# STM32F303VCY7 register map
File version: 1.0
STM32F303CBT6,STM32F303CBT7,STM32F303CCT6,STM32F303CCT7,STM32F303RBT6,STM32F303RBT7,STM32F303RCT6,STM32F303RCT7,STM32F303VBT6,STM32F303VBT7,STM32F303VCT6,STM32F303VCT7,STM32F303VCY6,STM32F303VCY7
Registers are 32-bit, access not given, reset 0x0 unless marked. A register's access mark holds for its fields unless they carry their own. Offsets are from the block's base; lines under a group give offsets from that group; [hi:lo] are bit positions; {n}, {i} and the like mark numbered series; 'fields as' and 'values as' point back to an identical list; <NAME> marks a mode.

## Memory map
0x1FFFF800 OB
0x40000000 TIM2
0x40000400 TIM3
0x40000800 TIM4
0x40001000 TIM6
0x40001400 TIM7
0x40002800 RTC
0x40002C00 WWDG
0x40003000 IWDG
0x40003400 I2S2ext
0x40003800 SPI2
0x40003C00 SPI3
0x40004000 I2S3ext
0x40004400 USART2
0x40004800 USART3
0x40004C00 UART4
0x40005000 UART5
0x40005400 I2C1
0x40005800 I2C2
0x40006400 CAN
0x40007000 PWR
0x40007400 DAC
0x40007400 DAC1
0x40010000 SYSCFG
0x4001001C COMP1
0x4001001C COMP
0x40010020 COMP2
0x40010020 COMP12_COMMON
0x40010024 COMP3
0x40010028 COMP4
0x40010028 COMP34_COMMON
0x4001002C COMP5
0x40010030 COMP6
0x40010030 COMP56_COMMON
0x40010034 COMP7
0x40010038 OPAMP1
0x40010038 OPAMP
0x4001003C OPAMP2
0x40010040 OPAMP3
0x40010044 OPAMP4
0x40010400 EXTI
0x40012C00 TIM1
0x40013000 SPI1
0x40013400 TIM8
0x40013800 USART1
0x40014000 TIM15
0x40014400 TIM16
0x40014800 TIM17
0x40020000 DMA1
0x40020400 DMA2
0x40021000 RCC
0x40022000 FLASH
0x40023000 CRC
0x40024000 TSC
0x48000000 GPIOA
0x48000400 GPIOB
0x48000800 GPIOC
0x48000C00 GPIOD
0x48001000 GPIOE
0x48001400 GPIOF
0x50000000 ADC1
0x50000100 ADC2
0x50000300 ADC12_COMMON
0x50000400 ADC3
0x50000500 ADC4
0x50000700 ADC34_COMMON
0xE0042000 DBGMCU

## OB
Base 0x1FFFF800
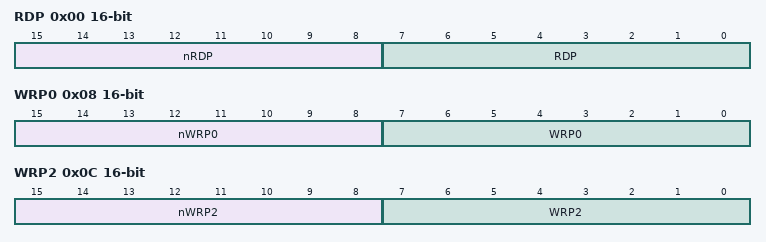
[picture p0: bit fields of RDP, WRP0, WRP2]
0x00 RDP 16-bit
  [15:8] nRDP, [7:0] RDP
0x02 USER 16-bit
  [31:24] nUSER, [23:16] USER
0x04 Data0 16-bit
0x06 Data1 16-bit
0x08 WRP0 16-bit
  [15:8] nWRP0, [7:0] WRP0
0x0A WRP1 16-bit
  [31:24] nWRP1, [23:16] WRP1
0x0C WRP2 16-bit
  [15:8] nWRP2, [7:0] WRP2
0x0E WRP3 16-bit
  [31:24] nWRP3, [23:16] WRP3

## TIM2
Base 0x40000000
Same registers: TIM3 0x40000400, TIM4 0x40000800, TIM6 0x40001000, TIM7 0x40001400, TIM1 0x40012C00, TIM8 0x40013400, TIM15 0x40014000, TIM16 0x40014400, TIM17 0x40014800
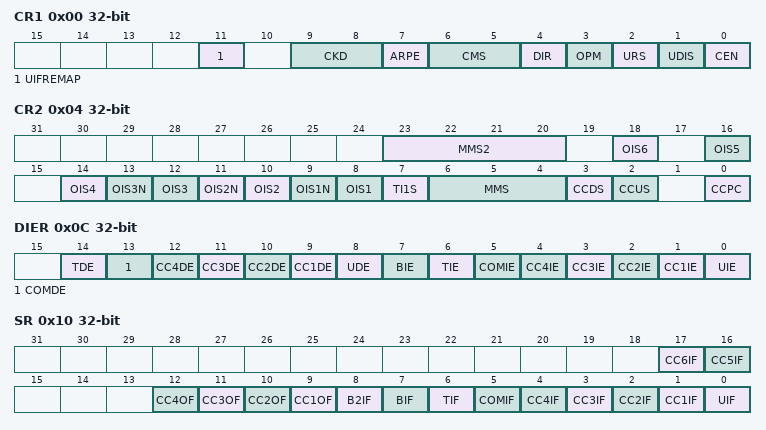
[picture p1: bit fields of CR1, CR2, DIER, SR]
0x00 CR1
  [11] UIFREMAP, [9:8] CKD, [7] ARPE, [6:5] CMS, [4] DIR, [3] OPM, [2] URS, [1] UDIS, [0] CEN
0x04 CR2
  [23:20] MMS2, [2n+6] OIS{n} (n=1..6), [13] OIS3N, [11] OIS2N, [9] OIS1N, [7] TI1S, [6:4] MMS, [3] CCDS, [2] CCUS, [0] CCPC
0x08 SMCR
  [15] ETP, [14] ECE, [13:12] ETPS, [11:8] ETF, [7] MSM, [6:4] TS, [3] OCCS, [16:0] SMS
0x0C DIER
  [14] TDE, [13] COMDE, [n+8] CC{n}DE (n=1..4), [8] UDE, [7] BIE, [6] TIE, [5] COMIE, [n] CC{n}IE (n=1..4), [0] UIE
0x10 SR
  [17] CC6IF, [16] CC5IF, [n+8] CC{n}OF (n=1..4), [8] B2IF, [7] BIF, [6] TIF, [5] COMIF, [n] CC{n}IF (n=1..4), [0] UIF
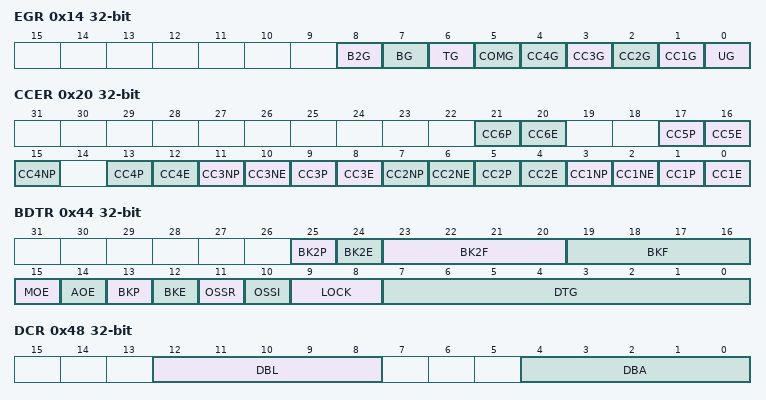
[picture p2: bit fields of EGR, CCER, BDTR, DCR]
0x14 EGR
  [8] B2G, [7] BG, [6] TG, [5] COMG, [n] CC{n}G (n=1..4), [0] UG
0x18 CCMR1
  [15] OC2CE, [24:12] OC2M, [11] OC2PE, [10] OC2FE, [9:8] CC2S, [7] OC1CE, [16:4] OC1M, [3] OC1PE, [2] OC1FE, [1:0] CC1S
0x1C CCMR2
  [15] OC4CE, [24:12] OC4M, [11] OC4PE, [10] OC4FE, [9:8] CC4S, [7] OC3CE, [16:4] OC3M, [3] OC3PE, [2] OC3FE, [1:0] CC3S
0x20 CCER
  [4n-3] CC{n}P (n=1..6), [4n-4] CC{n}E (n=1..6), [4n-1] CC{n}NP (n=1..4), [10] CC3NE, [6] CC2NE, [2] CC1NE
0x24 CNT
  [31] UIFCPY, [31:0] CNT
0x28 PSC
  [15:0] PSC
0x2C ARR
0x30 RCR
  [15:0] REP
{0x30+4i} CCR{i} (i=1..4)
  [15:0] CCR{i}
0x44 BDTR
  [25] BK2P, [24] BK2E, [23:20] BK2F, [19:16] BKF, [15] MOE, [14] AOE, [13] BKP, [12] BKE, [11] OSSR, [10] OSSI, [9:8] LOCK, [7:0] DTG
0x48 DCR
  [12:8] DBL, [4:0] DBA
0x4C DMAR
  [15:0] DMAB
0x50 OR
0x54 CCMR3
  [15] OC6CE, [24:12] OC6M, [11] OC6PE, [10] OC6FE, [7] OC5CE, [16:4] OC5M, [3] OC5PE, [2] OC5FE
0x58 CCR5
  [31] GC5C3, [30] GC5C2, [29] GC5C1, [31:0] CCR5
0x5C CCR6
  [15:0] CCR6

## RTC
Base 0x40002800
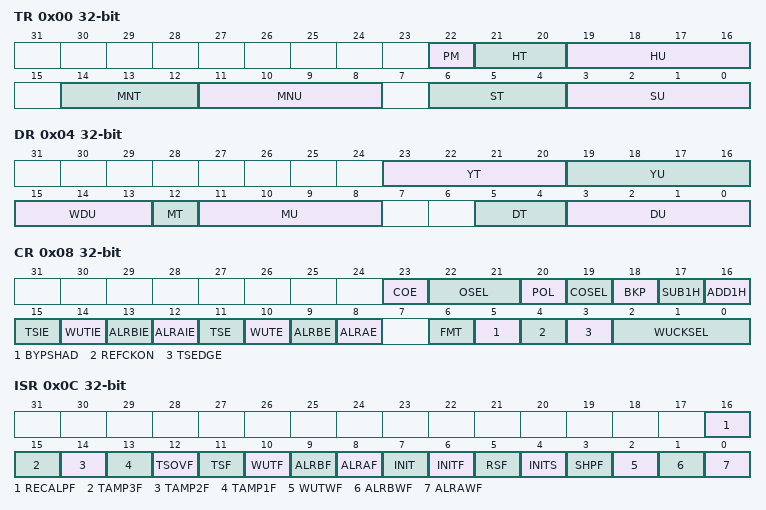
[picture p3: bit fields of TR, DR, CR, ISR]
0x00 TR
  [22] PM, [21:20] HT, [19:16] HU, [14:12] MNT, [11:8] MNU, [6:4] ST, [3:0] SU
0x04 DR
  [23:20] YT, [19:16] YU, [15:13] WDU, [12] MT, [11:8] MU, [5:4] DT, [3:0] DU
0x08 CR
  [23] COE, [22:21] OSEL, [20] POL, [19] COSEL, [18] BKP, [17] SUB1H, [16] ADD1H, [15] TSIE, [14] WUTIE, [13] ALRBIE, [12] ALRAIE, [11] TSE, [10] WUTE, [9] ALRBE, [8] ALRAE, [6] FMT, [5] BYPSHAD, [4] REFCKON, [3] TSEDGE, [2:0] WUCKSEL
0x0C ISR
  [16] RECALPF, [15] TAMP3F, [14] TAMP2F, [13] TAMP1F, [12] TSOVF, [11] TSF, [10] WUTF, [9] ALRBF, [8] ALRAF, [7] INIT, [6] INITF, [5] RSF, [4] INITS, [3] SHPF, [2] WUTWF, [1] ALRBWF, [0] ALRAWF
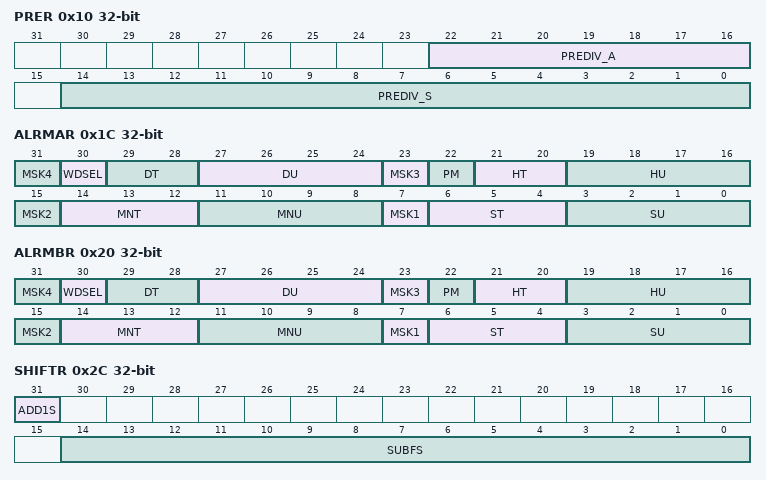
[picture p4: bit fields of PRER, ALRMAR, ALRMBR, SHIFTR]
0x10 PRER
  [22:16] PREDIV_A, [14:0] PREDIV_S
0x14 WUTR
  [15:0] WUT
0x1C ALRMAR
  [8n-1] MSK{n} (n=1..4), [30] WDSEL, [29:28] DT, [27:24] DU, [22] PM, [21:20] HT, [19:16] HU, [14:12] MNT, [11:8] MNU, [6:4] ST, [3:0] SU
0x20 ALRMBR
  fields as ALRMAR
0x24 WPR
  [7:0] KEY
0x28 SSR
  [15:0] SS
0x2C SHIFTR
  [31] ADD1S, [14:0] SUBFS
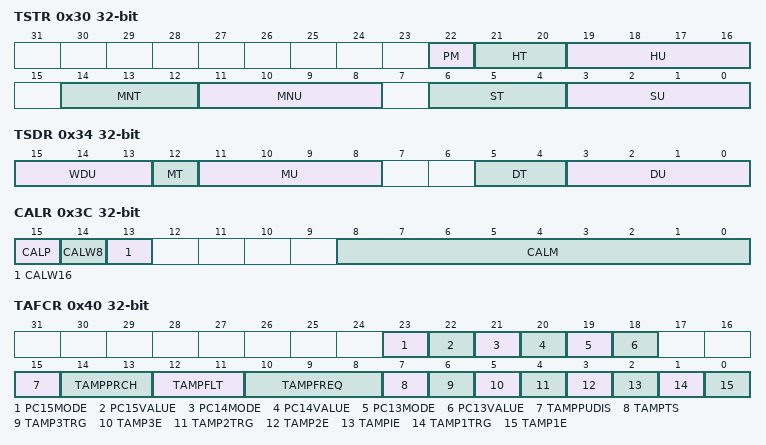
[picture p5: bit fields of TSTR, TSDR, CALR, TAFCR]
0x30 TSTR
  fields as TR
0x34 TSDR
  [15:13] WDU, [12] MT, [11:8] MU, [5:4] DT, [3:0] DU
0x38 TSSSR
  [15:0] SS
0x3C CALR
  [15] CALP, [14] CALW8, [13] CALW16, [8:0] CALM
0x40 TAFCR
  [23] PC15MODE, [22] PC15VALUE, [21] PC14MODE, [20] PC14VALUE, [19] PC13MODE, [18] PC13VALUE, [15] TAMPPUDIS, [14:13] TAMPPRCH, [12:11] TAMPFLT, [10:8] TAMPFREQ, [7] TAMPTS, [6] TAMP3TRG, [5] TAMP3E, [4] TAMP2TRG, [3] TAMP2E, [2] TAMPIE, [1] TAMP1TRG, [0] TAMP1E
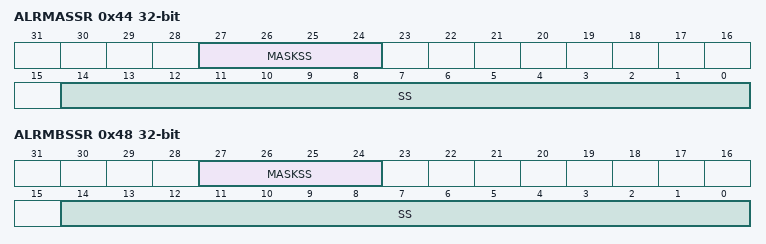
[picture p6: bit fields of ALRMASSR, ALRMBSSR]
0x44 ALRMASSR
  [27:24] MASKSS, [14:0] SS
0x48 ALRMBSSR
  [27:24] MASKSS, [14:0] SS
{0x50+4i} BKP{i}R (i=0..15)
